# colorlight register map
Vendor: litex
Registers are 32-bit, read-write, reset 0x0 unless marked. A register's access mark holds for its fields unless they carry their own. Offsets are from the block's base; [hi:lo] are bit positions; lines under a group give offsets from that group; 'fields as' and 'values as' point back to an identical list.

## HUB75
Base 0xF0005800
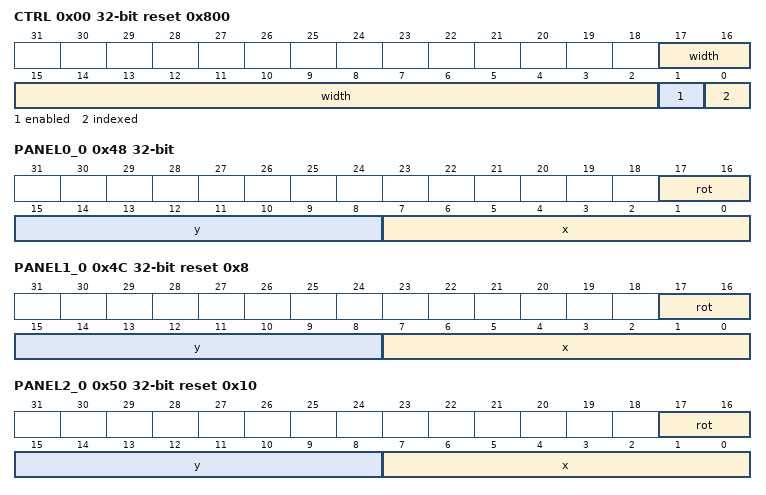
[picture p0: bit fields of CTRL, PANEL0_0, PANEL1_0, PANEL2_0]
0x00 CTRL reset 0x800
  [17:2] width — Framebuffer stride in pixels (the layout's virtual width)
  [1] enabled — Enable the output
  [0] indexed — Pixels are palette indices (low byte), looked up before gamma
0x04 FB_BASE
  [19:0] offset — Framebuffer base in 32-bit words
0x08 RGB_ORDER — Module channel order, indexes RGB_ORDERS (0=RGB, 1=RBG, 2=GRB, 3=GBR, 4=BRG, 5=BGR)
  [2:0] rgb_order
0x0C AUTO_SWAP — Flip the framebuffer in gateware at each frame boundary
  [0] auto_swap
0x10 FB_BASE_NOW — Framebuffer half currently displayed (follows auto_swap)
  [19:0] fb_base_now
0x14 UNDERRUNS — Pixels the serialiser latched before their memory read returned. Every one is a wrong pixel on the glass. Zero is the target.
0x18 PERF_FILL_CYCLES — sys clocks output 0 was filling a row
0x1C PERF_FILLS — rows output 0 filled
0x20 PERF_CMDS — read commands accepted by the SDRAM port
0x24 PERF_STALL — clocks a read command waited for the port
0x28 HW_COLUMNS reset 0x80 — Module width in pixels, as one output drives it (read-only)
  [15:0] hw_columns
0x2C HW_ROWS reset 0x100 — Module height in pixels, as one output drives it (read-only)
  [15:0] hw_rows
0x30 HW_CONFIG reset 0x4440 — scan[7:0], rgb_groups[11:8], n_outputs[15:12]
  [15:0] hw_config
0x34 HW_CHIP reset 0x2 — Default chip table index (see spwm_chips.CHIPS)
  [7:0] hw_chip
0x38 HW_DRIVER reset 0x1 — Output stage: 0 = HUB75 bit-plane, 1 = ICND1065 S-PWM
  [7:0] hw_driver
0x3C HW_CLK_DIV reset 0x4 — Panel shift clock divider (sys/N)
  [7:0] hw_clk_div
0x40 HW_PIX_BITS reset 0x20 — Framebuffer bits per pixel: 32 (0x00BBGGRR) or 16 (B5G6R5)
  [7:0] hw_pix_bits
0x44 REFRESH_COUNT — Completed frames
0x48 PANEL0_0
  [17:16] rot — rotation, not implemented in this stage
  [15:8] y — y position in multiples of 16
  [7:0] x — x position in multiples of 16
0x4C PANEL1_0 reset 0x8
  fields as PANEL0_0
0x50 PANEL2_0 reset 0x10
  fields as PANEL0_0
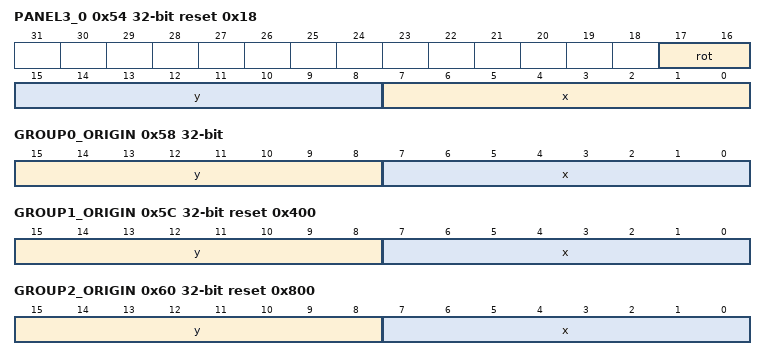
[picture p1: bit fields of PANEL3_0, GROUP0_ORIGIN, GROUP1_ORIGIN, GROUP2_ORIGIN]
0x54 PANEL3_0 reset 0x18
  fields as PANEL0_0
0x58 GROUP0_ORIGIN
  [15:8] y — group strip y origin in the module, multiples of 16
  [7:0] x — group strip x origin in the module, multiples of 16
0x5C GROUP1_ORIGIN reset 0x400
  fields as GROUP0_ORIGIN
0x60 GROUP2_ORIGIN reset 0x800
  fields as GROUP0_ORIGIN
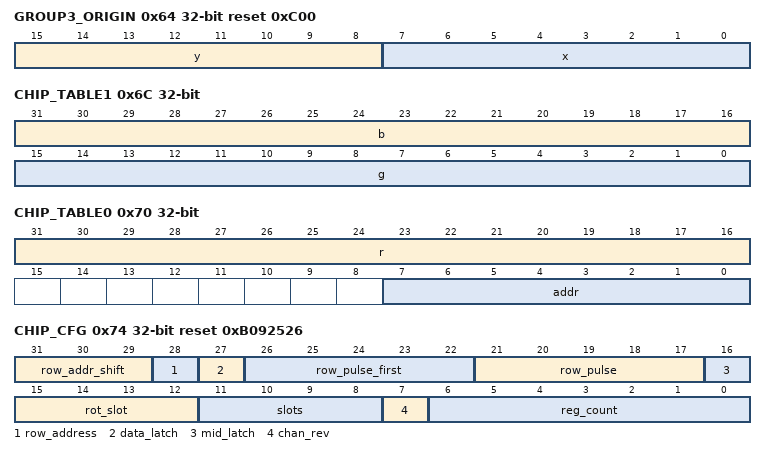
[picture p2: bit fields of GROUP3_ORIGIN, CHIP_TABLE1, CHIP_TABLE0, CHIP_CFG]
0x64 GROUP3_ORIGIN reset 0xC00
  fields as GROUP0_ORIGIN
0x68 HW_PALETTE_BANKS reset 0x2 — Palette banks in this bitstream (2 = flips with the framebuffer)
  [3:0] hw_palette_banks
0x6C CHIP_TABLE1 — Bits 32-63 of `HUB75_CHIP_TABLE`. Write one row of the chip register table
  [31:16] b — blue lane word
  [15:0] g — green lane word
0x70 CHIP_TABLE0 — Bits 0-31 of `HUB75_CHIP_TABLE`.
  [31:16] r — red lane word
  [7:0] addr — Table row: 0..MAX_REGS-1 registers, then wrappers
0x74 CHIP_CFG reset 0xB092526 — Chip grammar; reset values are the built-in default
  [31:29] row_addr_shift — Low bits of the row to drop before A/B/C
  [28] row_address — Drive A-E with the scanned row number
  [27] data_latch — Pulse LAT at the end of each row of pixels
  [26:22] row_pulse_first — ROW pulse width for the first row of a frame
  [21:17] row_pulse — ROW pulse width in panel clocks
  [16] mid_latch — Send the middle 11-clock LAT burst
  [15:12] rot_slot — Which slot carries the rotating register
  [11:8] slots — Register slots per frame prefix
  [7] chan_rev — Send a line channel 15->0 (11.2) not 0->15
  [6:0] reg_count — Registers in the rotation
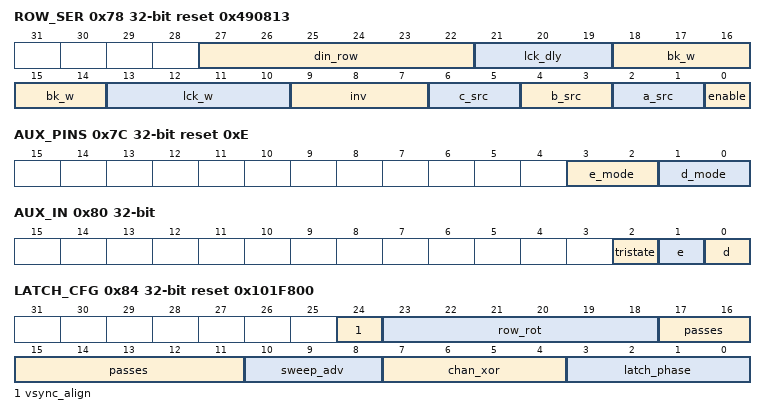
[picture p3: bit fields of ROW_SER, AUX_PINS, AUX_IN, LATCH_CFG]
0x78 ROW_SER reset 0x490813 — Serial row-driver mapping; all of it live
  [27:22] din_row — Scan row at which DIN is injected (0 = row 0)
  [21:19] lck_dly — Bit periods DIN is held before LCK rises
  [18:14] bk_w — BK assert width across the row change
  [13:10] lck_w — LCK high width, in panel bit periods
  [9:7] inv — Invert pins 17/18/19 after selection
  [6:5] c_src — Pin 19: 0=DIN 1=LCK 2=BK 3=low
  [4:3] b_src — Pin 18: 0=DIN 1=LCK 2=BK 3=low
  [2:1] a_src — Pin 17: 0=DIN 1=LCK 2=BK 3=low
  [0] enable — Drive A/B/C as a serial row chain, not an address
0x7C AUX_PINS reset 0xE — HUB320 pins 20/21 drive; reset value is the safe one
  [3:2] e_mode — Pin 21: 0=row E 1=low 2=high 3=hi-Z
  [1:0] d_mode — Pin 20: 0=row D 1=low 2=high 3=hi-Z
0x80 AUX_IN — HUB320 pins 20/21 read back from the pads
  [2] tristate — 1 if this build tri-states pins 20/21
  [1] e — Pin 21 as read
  [0] d — Pin 20 as read
0x84 LATCH_CFG reset 0x101F800
  [24] vsync_align — Start each data frame (its VSYNC) only at the start of a row-scan pass. For chips that reset their line counter on VSYNC while ROW free-runs (ICND1065L): without it the picture rotates by a different amount every frame and scrolls.
  [23:18] row_rot — Rotate the rows FETCHED for each scan line: scan line s shows framebuffer row (s + row_rot) mod scan within every group. The Myled P1.25 (ICND1065L + ICND1028AP) lit row s+32 for line s, and the row chain's DIN had no effect on it (2026-11-15), so the offset is fixed on the data side. 0 is no rotation.
  [17:11] passes — Display passes per data frame MINUS ONE -- the chip's own reg0x03. The wide W12 ROW pulse fires on row 0 of every (passes + 1)-th pass (11.6.2), and the SAME number sets the chip's displayable grey range, 4 x (reg0x04 + 1) x (passes + 1) (11.7.5). Runtime because each value otherwise costs a power cycle: too few and every mixed colour clips to full, too many and the W12 cadence drifts against the row chain (the 'rain' of 4.4). MUST match reg0x03 in the chip table.
  [10:8] sweep_adv — Advance the FETCH ADDRESS by N sweeps, carrying into the row, WITHOUT changing the latch count. Not latch_phase: that adds DATA_LATCH pulses and moves our data LATER against the chip's line boundary; this moves the DATA EARLIER and leaves the count at 16 per row. The 16-pitch dots sit at the columns fed by sweep 0 -- the first latch of every row, in all eight chips -- and carry the adjacent row's value, while simulation proves our first latch commits the RIGHT row's data. That means the chip's line advance lands one latch later than ours, and this is the lever for it. 0 is no correction.
  [7:4] chan_xor — XOR applied to the channel index -- a permutation of the sixteen columns inside every driver. 1 is the measured pair swap for this module. This belongs in the gateware rather than in the firmware's pattern generator, because STREAMED content writes the framebuffer directly and never sees a pattern-side correction; 0 is identity.
  [3:0] latch_phase — Extra DATA_LATCH pulses emitted after the frame prefix. Tested 0, 1 and 15 on hardware 2026-10-19: the pulses reach the chip (verified 1024 -> 1025 -> 1027 in simulation at the real geometry) and the picture does not move, so the 16-pitch dots are NOT a write-pointer phase error. Kept as an instrument; 0 is no correction.
0x88 CLK_DIV reset 0x4 — Panel shift clock divider, sys/N. Clamped to N>=2, so at 35 MHz the range is 17.5 MHz down to 137 kHz. Live.
  [7:0] clk_div
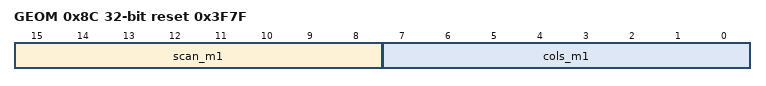
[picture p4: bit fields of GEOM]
0x8C GEOM reset 0x3F7F — Module geometry inside the build's maxima. Write with the display off.
  [15:8] scan_m1 — Scan lines, minus one. An even count, at most this build's maximum.
  [7:0] cols_m1 — Columns in one RGB group's chain, minus one. A whole number of 16-channel chips, at most this build's hw maximum.
